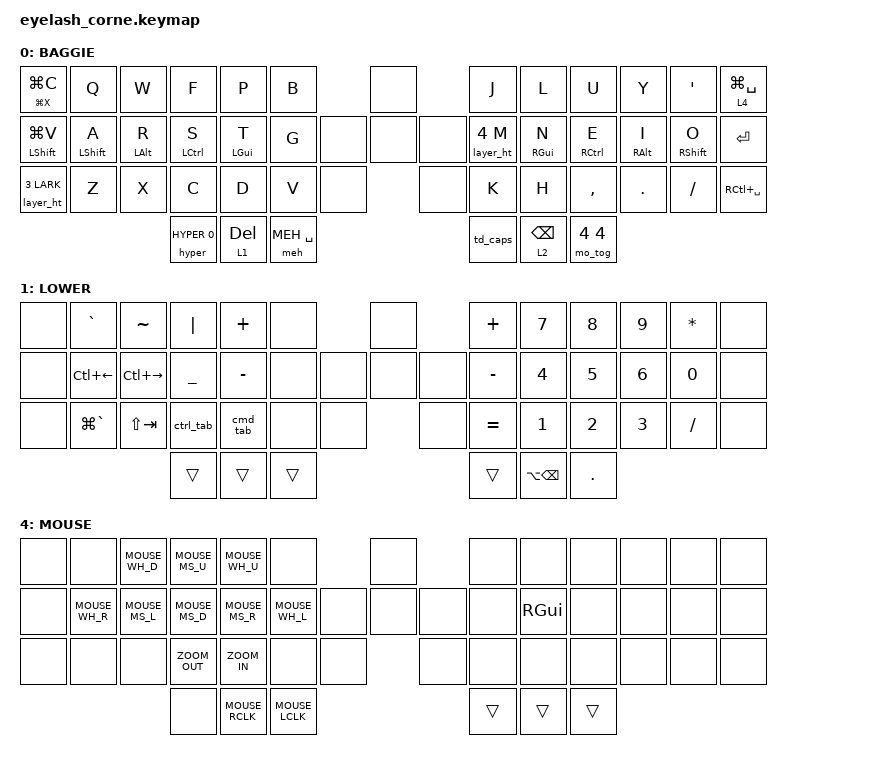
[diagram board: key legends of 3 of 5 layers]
#include <behaviors.dtsi>
#include <dt-bindings/zmk/bt.h>
#include <dt-bindings/zmk/keys.h>

#include "includes/behaviors_tristate.dtsi"
#include "includes/behaviors_tapdances.dtsi"
#include "includes/behaviors_holdtaps.dtsi"
#include "includes/mouse.dtsi"
#include "includes/combos.dtsi"

#define MEH LS(LC(LALT))
#define HYPER LG(LS(LC(LALT)))
#define LARK LG(LS(D))

#define _BT_SEL_KEYS_           &bt BT_SEL 0 &bt BT_SEL 1 &bt BT_SEL 2 &bt BT_SEL 3 &bt BT_SEL 4 &td_bluetooth
#define _MEDIA_CONTROL_         &kp C_VOLUME_DOWN  &kp C_VOLUME_UP  &kp C_MUTE  &kp C_PLAY_PAUSE
#define _HOME_ROW_ARROW_        &ht LA(LEFT) LEFT  &kp DOWN  &kp UP  &ht LA(RIGHT) RIGHT
#define _BRIGHTNESS_CONTROL_    &kp C_BRIGHTNESS_DEC  &kp C_BRIGHTNESS_INC  
#define _SCREENSHOT_SHORTCUT_   &kp LS(LG(N2))    &kp LS(LG(N3))  &kp LS(LG(N4))


&sk {
    release-after-ms = <2000>;
    quick-release;
    /delete-property/ ignore-modifiers;
};
&sl {
    release-after-ms = <1000>;
    
    // quick-release enabled: sticky key is released when the next key is pressed
    // disabled: sticky key is released when the next key is released
    // in order to long press mouse keys, quick release should be disabled
    // quick-release;

    /delete-property/ ignore-modifiers;
};
&lt {
    tapping-term-ms = <220>;
    // quick tap lt twice to send backspace
    quick-tap-ms = <220>;
    flavor = "hold-preferred";
};

/ {

    keymap {
        compatible = "zmk,keymap";

        default_layer {
            display-name = "BAGGIE";
            bindings = <
// ╭─────────────┬─────────────┬─────────────┬─────────────┬─────────────┬─────────────╮                    ╭─────────────┬─────────────┬─────────────┬─────────────┬─────────────┬─────────────╮
     &ht LG(X) LG(C)    &kp Q    &kp W         &kp F         &kp P         &kp B               &none          &kp J         &kp L         &kp U         &kp Y         &kp SQT       &lt 4 LG(SPACE)
// ├─────────────┼─────────────┼─────────────┼─────────────┼─────────────┼─────────────┤                    ├─────────────┼─────────────┼─────────────┼─────────────┼─────────────┼─────────────┤
     &ht LSHFT LG(V)    &hm LSHFT A  &hm LALT R  &hm LCTRL S  &hm LGUI T   &kp G         &none &none &none    &layer_ht 4 M  &hm RGUI N   &hm RCTRL E   &hm RALT I    &hm RSHFT O   &kp ENTER
// ├─────────────┼─────────────┼─────────────┼─────────────┼─────────────┼─────────────┤                    ├─────────────┼─────────────┼─────────────┼─────────────┼─────────────┼─────────────┤
     &layer_ht 3 LARK   &kp Z    &kp X         &kp C         &kp D         &kp V           &none   &none      &kp K         &kp H         &kp COMMA     &kp DOT       &kp FSLH      &kp RC(SPACE)
// ╰─────────────┴─────────────┴─────────────┼─────────────┼─────────────┼─────────────┤                    ├─────────────┼─────────────┼─────────────┼─────────────┴─────────────┴─────────────╯
                                              &hyper HYPER 0  &lt 1 DEL    &meh MEH SPACE                     &td_caps     &lt 2 BSPC    &mo_tog 4 4
//                                           ╰─────────────┴─────────────┴─────────────╯                    ╰─────────────┴─────────────┴─────────────╯
            >;
        };

        lower_layer {
            display-name = "LOWER";
            bindings = <
// ╭─────────────┬─────────────┬─────────────┬─────────────┬─────────────┬─────────────╮                    ╭─────────────┬─────────────┬─────────────┬─────────────┬─────────────┬─────────────╮
     &none         &kp GRAVE     &kp TILDE      &kp PIPE     &kp PLUS      &none               &none          &kp PLUS      &kp N7        &kp N8        &kp N9        &kp STAR      &none 
// ├─────────────┼─────────────┼─────────────┼─────────────┼─────────────┼─────────────┤                    ├─────────────┼─────────────┼─────────────┼─────────────┼─────────────┼─────────────┤
     &none         &kp LC(LEFT)  &kp LC(RIGHT)  &kp UNDER    &kp MINUS     &none         &none &none &none    &kp MINUS     &kp N4        &kp N5        &kp N6        &kp N0        &none 
// ├─────────────┼─────────────┼─────────────┼─────────────┼─────────────┼─────────────┤                    ├─────────────┼─────────────┼─────────────┼─────────────┼─────────────┼─────────────┤
     &none         &kp LG(GRAVE)  &kp LS(TAB)   &ctrl_tab    &cmd_tab      &none           &none   &none      &kp EQUAL     &kp N1        &kp N2        &kp N3        &kp FSLH      &none 
// ╰─────────────┴─────────────┴─────────────┼─────────────┼─────────────┼─────────────┤                    ├─────────────┼─────────────┼─────────────┼─────────────┴─────────────┴─────────────╯
                                               &trans        &trans        &trans                             &trans        &kp LA(BSPC)  &kp DOT
//                                           ╰─────────────┴─────────────┴─────────────╯                    ╰─────────────┴─────────────┴─────────────╯
            >;
        };

        raise_layer {
            display-name = "UPPER";
            bindings = <
// ╭─────────────┬─────────────┬─────────────┬─────────────┬─────────────┬─────────────╮                    ╭─────────────┬─────────────┬─────────────┬─────────────┬─────────────┬─────────────╮
     &none         &kp DLLR      &kp HASH      &kp LBRC      &kp RBRC      &none               &none          &none         &kp AMPS      &kp STAR      &kp SEMI      &kp DQT       &none 
// ├─────────────┼─────────────┼─────────────┼─────────────┼─────────────┼─────────────┤                    ├─────────────┼─────────────┼─────────────┼─────────────┼─────────────┼─────────────┤
     &none         &kp AT        &kp EXCL      &kp LPAR      &kp RPAR      &none         &none &none &none                      _HOME_ROW_ARROW_                      &kp COLON     &none 
// ├─────────────┼─────────────┼─────────────┼─────────────┼─────────────┼─────────────┤                    ├─────────────┼─────────────┼─────────────┼─────────────┼─────────────┼─────────────┤
     &none         &kp CARET     &kp PRCNT     &kp LBKT      &kp RBKT      &none           &none   &none      &kp END      &kp PAGE_DOWN   &kp PAGE_UP  &kp HOME      &kp BSLH      &none 
// ╰─────────────┴─────────────┴─────────────┼─────────────┼─────────────┼─────────────┤                    ├─────────────┼─────────────┼─────────────┼─────────────┴─────────────┴─────────────╯
                                               &trans        &kp RA(DEL)   &trans                             &trans        &trans        &trans 
//                                           ╰─────────────┴─────────────┴─────────────╯                    ╰─────────────┴─────────────┴─────────────╯
            >;
        };

        controls {
            display-name = "CTRL";
            bindings = <
// ╭─────────────┬─────────────┬─────────────┬─────────────┬─────────────┬─────────────╮                    ╭─────────────┬─────────────┬─────────────┬─────────────┬─────────────┬─────────────╮
     &none         &none         &none         &none         &none         &bootloader         &none                           _BT_SEL_KEYS_
// ├─────────────┼─────────────┼─────────────┼─────────────┼─────────────┼─────────────┤                    ├─────────────┼─────────────┼─────────────┼─────────────┼─────────────┼─────────────┤
     &none         &none           _BRIGHTNESS_CONTROL_     &kp LG(MINUS)  &kp LG(EQUAL) &none &none &none    &kp F7        &kp F8        &kp F9        &kp F10       &kp F11       &kp F12
// ├─────────────┼─────────────┼─────────────┼─────────────┼─────────────┼─────────────┤                    ├─────────────┼─────────────┼─────────────┼─────────────┼─────────────┼─────────────┤
     &none         &kp LS(LG(N1))                  _MEDIA_CONTROL_                         &none   &none      &kp F1        &kp F2        &kp F3        &kp F4        &kp F5        &kp F6
// ╰─────────────┴─────────────┴─────────────┼─────────────┼─────────────┼─────────────┤                    ├─────────────┼─────────────┼─────────────┼─────────────┴─────────────┴─────────────╯
                                                        _SCREENSHOT_SHORTCUT_                                 &trans        &trans        &bootloader 
//                                           ╰─────────────┴─────────────┴─────────────╯                    ╰─────────────┴─────────────┴─────────────╯
            >;
        };

        mouse {
            display-name = "MOUSE";
            bindings = <
// ╭─────────────┬─────────────┬─────────────┬─────────────┬─────────────┬─────────────╮                    ╭─────────────┬─────────────┬─────────────┬─────────────┬─────────────┬─────────────╮
     &none         &none         MOUSE_WH_D    MOUSE_MS_U    MOUSE_WH_U    &none               &none          &none         &none         &none         &none         &none         &none
// ├─────────────┼─────────────┼─────────────┼─────────────┼─────────────┼─────────────┤                    ├─────────────┼─────────────┼─────────────┼─────────────┼─────────────┼─────────────┤
     &none         MOUSE_WH_R    MOUSE_MS_L    MOUSE_MS_D    MOUSE_MS_R    MOUSE_WH_L    &none &none &none    &none         &kp RGUI      &none         &none         &none         &none
// ├─────────────┼─────────────┼─────────────┼─────────────┼─────────────┼─────────────┤                    ├─────────────┼─────────────┼─────────────┼─────────────┼─────────────┼─────────────┤
     &none         &none         &none          ZOOM_OUT      ZOOM_IN      &none           &none   &none      &none         &none         &none         &none         &none         &none
// ╰─────────────┴─────────────┴─────────────┼─────────────┼─────────────┼─────────────┤                    ├─────────────┼─────────────┼─────────────┼─────────────┴─────────────┴─────────────╯
                                               &none         MOUSE_RCLK    MOUSE_LCLK                         &trans        &trans        &trans 
//                                           ╰─────────────┴─────────────┴─────────────╯                    ╰─────────────┴─────────────┴─────────────╯
            >;
        };
    };
};

